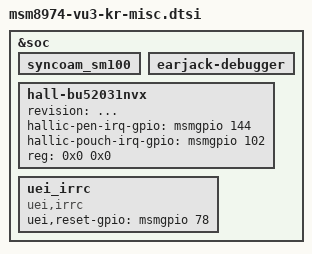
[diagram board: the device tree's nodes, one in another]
/* Copyright (c) 2012, Code Aurora Forum. All rights reserved.
 *
 * This program is free software; you can redistribute it and/or modify
 * it under the terms of the GNU General Public License version 2 and
 * only version 2 as published by the Free Software Foundation.
 *
 * This program is distributed in the hope that it will be useful,
 * but WITHOUT ANY WARRANTY; without even the implied warranty of
 * MERCHANTABILITY or FITNESS FOR A PARTICULAR PURPOSE.  See the
 * GNU General Public License for more details.
 */

&soc {
	syncoam_sm100 {

		status = "ok";
	};

	earjack-debugger {
		status = "ok";
	};

	hall-bu52031nvx {
		status = "ok";
		revision = "...";
		hallic-pen-irq-gpio = <&msmgpio 144 0x00>;
		hallic-pouch-irq-gpio = <&msmgpio 102 0x00>;
		reg = <0x0 0x0>;
	};

	uei_irrc {
		status = "ok";
	    compatible = "uei,irrc";
	    uei,reset-gpio = <&msmgpio 78 0x00>;
	};


};
